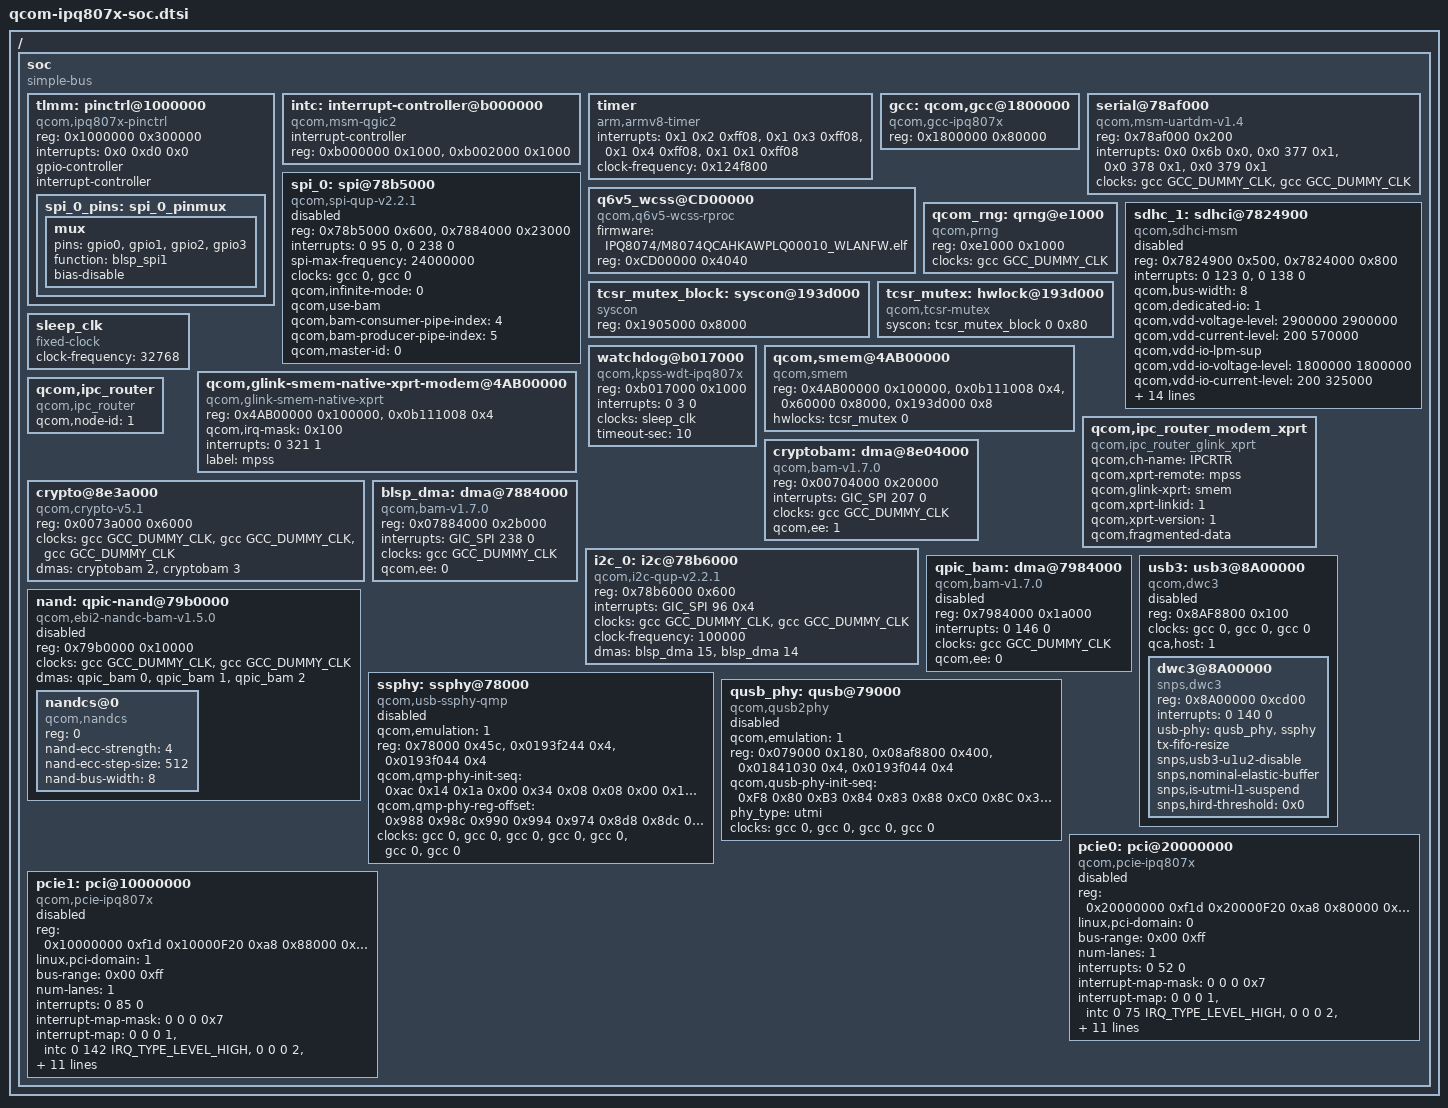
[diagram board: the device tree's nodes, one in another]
/*
 * Copyright (c) 2016, The Linux Foundation. All rights reserved.
 *
 * Permission to use, copy, modify, and/or distribute this software for any
 * purpose with or without fee is hereby granted, provided that the above
 * copyright notice and this permission notice appear in all copies.
 *
 * THE SOFTWARE IS PROVIDED "AS IS" AND THE AUTHOR DISCLAIMS ALL WARRANTIES
 * WITH REGARD TO THIS SOFTWARE INCLUDING ALL IMPLIED WARRANTIES OF
 * MERCHANTABILITY AND FITNESS. IN NO EVENT SHALL THE AUTHOR BE LIABLE FOR
 * ANY SPECIAL, DIRECT, INDIRECT, OR CONSEQUENTIAL DAMAGES OR ANY DAMAGES
 * WHATSOEVER RESULTING FROM LOSS OF USE, DATA OR PROFITS, WHETHER IN AN
 * ACTION OF CONTRACT, NEGLIGENCE OR OTHER TORTIOUS ACTION, ARISING OUT OF
 * OR IN CONNECTION WITH THE USE OR PERFORMANCE OF THIS SOFTWARE.
 */
#include <dt-bindings/reset/qcom,gcc-ipq807x.h>
#include <dt-bindings/interrupt-controller/arm-gic.h>

/ {
	soc: soc {
		#address-cells = <0x1>;
		#size-cells = <0x1>;
		ranges = <0x0 0x0 0x0 0xffffffff>;
		compatible = "simple-bus";

		tlmm: pinctrl@1000000 {
			compatible = "qcom,ipq807x-pinctrl";
			reg = <0x1000000 0x300000>;
			interrupts = <0x0 0xd0 0x0>;
			gpio-controller;
			#gpio-cells = <0x2>;
			interrupt-controller;
			#interrupt-cells = <0x2>;

			spi_0_pins: spi_0_pinmux {
				mux {
					pins = "gpio0", "gpio1", "gpio2", "gpio3";
					function = "blsp_spi1";
					bias-disable;
				};
			};
		};

		intc: interrupt-controller@b000000 {
			compatible = "qcom,msm-qgic2";
			interrupt-controller;
			#interrupt-cells = <0x3>;
			reg = <0xb000000 0x1000>,
			<0xb002000 0x1000>;
		};

		timer {
			compatible = "arm,armv8-timer";
			interrupts = <0x1 0x2 0xff08>,
				     <0x1 0x3 0xff08>,
				     <0x1 0x4 0xff08>,
				     <0x1 0x1 0xff08>;
			clock-frequency = <0x124f800>;
		};


		gcc: qcom,gcc@1800000 {
			compatible = "qcom,gcc-ipq807x";
			reg = <0x1800000 0x80000>;
			#clock-cells = <0x1>;
		};

		serial@78af000 {
			compatible = "qcom,msm-uartdm-v1.4", "qcom,msm-uartdm";
			reg = <0x78af000 0x200>;
			interrupts = <0x0 0x6b 0x0>,
					<0x0 377 0x1>,
					<0x0 378 0x1>,
					<0x0 379 0x1>;
			status = "ok";
			clocks = <&gcc GCC_DUMMY_CLK>,
				 <&gcc GCC_DUMMY_CLK>;
			clock-names = "core", "iface";
		};

		spi_0: spi@78b5000 { /* BLSP1 QUP1 */
			compatible = "qcom,spi-qup-v2.2.1";
			#address-cells = <1>;
			#size-cells = <0>;
			reg-names = "spi_physical", "spi_bam_physical";
			reg = <0x78b5000 0x600>,
				<0x7884000 0x23000>;
			interrupt-names = "spi_irq", "spi_bam_irq";
			interrupts = <0 95 0>, <0 238 0>;
			spi-max-frequency = <24000000>;
			clocks = <&gcc 0>, /*GCC_BLSP1_QUP1_SPI_APPS_CLK>,*/
				<&gcc 0>;/*GCC_BLSP1_AHB_CLK>;*/
			clock-names = "core", "iface";
			qcom,infinite-mode = <0>;
			qcom,use-bam;
			qcom,bam-consumer-pipe-index = <4>;
			qcom,bam-producer-pipe-index = <5>;
			qcom,master-id = <0>;
			status = "disabled";
		};

		q6v5_wcss@CD00000 {
			compatible = "qcom,q6v5-wcss-rproc";
			firmware = "IPQ8074/M8074QCAHKAWPLQ00010_WLANFW.elf";
			reg = <0xCD00000 0x4040>;
		};

		qcom_rng: qrng@e1000 {
			compatible = "qcom,prng";
			reg = <0xe1000 0x1000>;
			clocks = <&gcc GCC_DUMMY_CLK>;
			clock-names = "core";
		};

		sdhc_1: sdhci@7824900 {
			compatible = "qcom,sdhci-msm";
			reg = <0x7824900 0x500>, <0x7824000 0x800>;
			reg-names = "hc_mem", "core_mem";

			interrupts = <0 123 0>, <0 138 0>;
			interrupt-names = "hc_irq", "pwr_irq";

			qcom,bus-width = <8>;

			qcom,dedicated-io = <1>;

			/* device core power supply */
			qcom,vdd-voltage-level = <2900000 2900000>;
			qcom,vdd-current-level = <200 570000>;

			/* device communication power supply */
			qcom,vdd-io-lpm-sup;
			qcom,vdd-io-voltage-level = <1800000 1800000>;
			qcom,vdd-io-current-level = <200 325000>;
			qcom,vdd-io-always-on;

			qcom,cpu-dma-latency-us = <701>;
			qcom,msm-bus,name = "sdhc1";
			qcom,msm-bus,num-cases = <9>;
			qcom,msm-bus,num-paths = <1>;
			qcom,msm-bus,vectors-KBps = <78 512 0 0>, /* No vote */
				<78 512 1046 3200>,    /* 400 KB/s*/
				<78 512 52286 160000>, /* 20 MB/s */
				<78 512 65360 200000>, /* 25 MB/s */
				<78 512 130718 400000>, /* 50 MB/s */
				<78 512 261438 800000>, /* 100 MB/s */
				<78 512 261438 800000>, /* 200 MB/s */
				<78 512 261438 800000>, /* 400 MB/s */
				<78 512 1338562 4096000>; /* Max. bandwidth */
			qcom,bus-bw-vectors-bps = <0 400000 20000000 25000000 \
						50000000 100000000 200000000 \
						400000000 4294967295>;

			clocks = <&gcc GCC_DUMMY_CLK>,
				 <&gcc GCC_DUMMY_CLK>;
			clock-names = "iface_clk", "core_clk";
			qcom,large-address-bus;

			status = "disabled";
		};

		tcsr_mutex_block: syscon@193d000 {
			compatible = "syscon";
			reg = <0x1905000 0x8000>;
		};

		tcsr_mutex: hwlock@193d000 {
			compatible = "qcom,tcsr-mutex";
			syscon = <&tcsr_mutex_block 0 0x80>;
			#hwlock-cells = <1>;
		};

		sleep_clk: sleep_clk {
			compatible = "fixed-clock";
			clock-frequency = <32768>;
			#clock-cells = <0>;
		};

		watchdog@b017000 {
			compatible = "qcom,kpss-wdt-ipq807x";
			reg = <0xb017000 0x1000>;
			interrupt-names = "bark_irq";
			interrupts = <0 3 0>;
			clocks = <&sleep_clk>;
			timeout-sec = <10>;
		};

		qcom,smem@4AB00000 {
			compatible = "qcom,smem";
			reg = <0x4AB00000 0x100000>,
				<0x0b111008 0x4>,
				<0x60000 0x8000>,
				<0x193d000 0x8>;
			reg-names = "smem", "irq-reg-base",
				"aux-mem1", "smem_targ_info_reg";
			hwlocks = <&tcsr_mutex 0>;
		};

		qcom,glink-smem-native-xprt-modem@4AB00000 {
			compatible = "qcom,glink-smem-native-xprt";
			reg = <0x4AB00000 0x100000>, <0x0b111008 0x4>;
			reg-names = "smem", "irq-reg-base";
			qcom,irq-mask = <0x100>;
			interrupts = <0 321 1>;
			label = "mpss";
		};

		qcom,ipc_router {
			compatible = "qcom,ipc_router";
			qcom,node-id = <1>;
		};

		qcom,ipc_router_modem_xprt {
			compatible = "qcom,ipc_router_glink_xprt";
			qcom,ch-name = "IPCRTR";
			qcom,xprt-remote = "mpss";
			qcom,glink-xprt = "smem";
			qcom,xprt-linkid = <1>;
			qcom,xprt-version = <1>;
			qcom,fragmented-data;
		};

		cryptobam: dma@8e04000 {
			compatible = "qcom,bam-v1.7.0";
			reg = <0x00704000 0x20000>;
			interrupts = <GIC_SPI 207 0>;
			clocks = <&gcc GCC_DUMMY_CLK>;
			clock-names = "bam_clk";
			#dma-cells = <1>;
			qcom,ee = <1>;
		};

		crypto@8e3a000 {
			compatible = "qcom,crypto-v5.1";
			reg = <0x0073a000 0x6000>;
			clocks = <&gcc GCC_DUMMY_CLK>,
				<&gcc GCC_DUMMY_CLK>,
				<&gcc GCC_DUMMY_CLK>;
			clock-names = "iface", "bus", "core";
			dmas = <&cryptobam 2>, <&cryptobam 3>;
			dma-names = "rx", "tx";
		};

		blsp_dma: dma@7884000 {
			compatible = "qcom,bam-v1.7.0";
			reg = <0x07884000 0x2b000>;
			interrupts = <GIC_SPI 238 0>;
			clocks = <&gcc GCC_DUMMY_CLK>;
			clock-names = "bam_clk";
			#dma-cells = <1>;
			qcom,ee = <0>;
		};

		i2c_0: i2c@78b6000 {
			compatible = "qcom,i2c-qup-v2.2.1";
			#address-cells = <1>;
			#size-cells = <0>;
			reg = <0x78b6000 0x600>;
			interrupts = <GIC_SPI 96 0x4>;
			clocks = <&gcc GCC_DUMMY_CLK>,
				<&gcc GCC_DUMMY_CLK>;
			clock-names = "iface", "core";
			clock-frequency  = <100000>;
			dmas = <&blsp_dma 15>, <&blsp_dma 14>;
			dma-names = "rx", "tx";
		};

		qpic_bam: dma@7984000{
			compatible = "qcom,bam-v1.7.0";
			reg = <0x7984000 0x1a000>;
			interrupts = <0 146 0>;
			clocks = <&gcc GCC_DUMMY_CLK>;
			clock-names = "bam_clk";
			#dma-cells = <1>;
			qcom,ee = <0>;
			status = "disabled";
		};

		nand: qpic-nand@79b0000 {
			compatible = "qcom,ebi2-nandc-bam-v1.5.0";
			reg = <0x79b0000 0x10000>;
			#address-cells = <1>;
			#size-cells = <0>;
			clocks = <&gcc GCC_DUMMY_CLK>,
				<&gcc GCC_DUMMY_CLK>;
			clock-names = "core", "aon";

			dmas = <&qpic_bam 0>,
				<&qpic_bam 1>,
				<&qpic_bam 2>;
			dma-names = "tx", "rx", "cmd";
			status = "disabled";

			nandcs@0 {
				compatible = "qcom,nandcs";
				reg = <0>;
				#address-cells = <1>;
				#size-cells = <1>;

				nand-ecc-strength = <4>;
				nand-ecc-step-size = <512>;
				nand-bus-width = <8>;
			};
		};

		ssphy: ssphy@78000 {
			compatible = "qcom,usb-ssphy-qmp";
			qcom,emulation = <1>;
			reg = <0x78000 0x45c>,
				<0x0193f244 0x4>,
				<0x0193f044 0x4>;
			reg-names = "qmp_phy_base",
				    "vls_clamp_reg",
				    "tcsr_phy_clk_scheme_sel";
			qcom,qmp-phy-init-seq = <0xac 0x14 0x1a 0x00
						0x34 0x08 0x08 0x00
						0x174 0x30 0x30 0x00
						0x3c 0x06 0x06 0x00
						0xb4 0x00 0x00 0x00
						0xb8 0x08 0x08 0x00
						0x194 0x06 0x06 0x3e8
						0x19c 0x01 0x01 0x00
						0x178 0x00 0x00 0x00
						0xd0 0x82 0x82 0x00
						0xdc 0x55 0x55 0x00
						0xe0 0x55 0x55 0x00
						0xe4 0x03 0x03 0x00
						0x78 0x0b 0x0b 0x00
						0x84 0x16 0x16 0x00
						0x90 0x28 0x28 0x00
						0x108 0x80 0x80 0x00
						0x10c 0x00 0x00 0x00
						0x184 0x0a 0x0a 0x00
						0x4c 0x15 0x15 0x00
						0x50 0x34 0x34 0x00
						0x54 0x00 0x00 0x00
						0xc8 0x00 0x00 0x00
						0x18c 0x00 0x00 0x00
						0xcc 0x00 0x00 0x00
						0x128 0x00 0x00 0x00
						0x0c 0x0a 0x0a 0x00
						0x10 0x01 0x01 0x00
						0x1c 0x31 0x31 0x00
						0x20 0x01 0x01 0x00
						0x14 0x00 0x00 0x00
						0x18 0x00 0x00 0x00
						0x24 0xde 0xde 0x00
						0x28 0x07 0x07 0x00
						0x48 0x0f 0x0f 0x00
						0x70 0x0f 0x0f 0x00
						0x100 0x80 0x80 0x00
						0x440 0x0b 0x0b 0x00
						0x4d8 0x02 0x02 0x00
						0x4dc 0x6c 0x6c 0x00
						0x4e0 0xbb 0xbb 0x00
						0x508 0x77 0x77 0x00
						0x50c 0x80 0x80 0x00
						0x514 0x03 0x03 0x00
						0x51c 0x16 0x16 0x00
						0x448 0x75 0x75 0x00
						0x454 0x00 0x00 0x00
						0x40c 0x0a 0x0a 0x00
						0x41c 0x06 0x06 0x00
						0x510 0x00 0x00 0x00
						0x268 0x45 0x45 0x00
						0x2ac 0x12 0x12 0x00
						0x294 0x06 0x06 0x00
						0x254 0x00 0x00 0x00
						0x8c8 0x83 0x83 0x00
						0x8c4 0x02 0x02 0x00
						0x8cc 0x09 0x09 0x00
						0x8d0 0xa2 0xa2 0x00
						0x8d4 0x85 0x85 0x00
						0x880 0xd1 0xd1 0x00
						0x884 0x1f 0x1f 0x00
						0x888 0x47 0x47 0x00
						0x80c 0x9f 0x9f 0x00
						0x824 0x17 0x17 0x00
						0x828 0x0f 0x0f 0x00
						0x8b8 0x75 0x75 0x00
						0x8bc 0x13 0x13 0x00
						0x8b0 0x86 0x86 0x00
						0x8a0 0x04 0x04 0x00
						0x88c 0x44 0x44 0x00
						0x870 0xe7 0xe7 0x00
						0x874 0x03 0x03 0x00
						0x878 0x40 0x40 0x00
						0x87c 0x00 0x00 0x00
						0x9d8 0x88 0x88 0x00
						0xffffffff 0xffffffff 0x00 0x00>;
			qcom,qmp-phy-reg-offset = <0x988 0x98c 0x990 0x994
						0x974 0x8d8 0x8dc 0x804 0x800
						0x808>;

			clocks = <&gcc 0>,/*clk_gcc_usb3_aux_clk>,*/
				 <&gcc 0>,/*clk_gcc_usb3_pipe_clk>,*/
				 <&gcc 0>,/*clk_gcc_usb_phy_cfg_ahb_clk>,*/
				 <&gcc 0>,/*clk_gcc_usb3_phy_reset>,*/
				 <&gcc 0>,/*clk_gcc_usb3phy_phy_reset>,*/
				 <&gcc 0>,/*clk_bb_clk1>,*/
				 <&gcc 0>;/*clk_gcc_usb_ss_ref_clk>;*/

			clock-names = "aux_clk", "pipe_clk", "cfg_ahb_clk", "phy_reset",
				      "phy_phy_reset", "ref_clk_src", "ref_clk";

			status = "disabled";
		};

		qusb_phy: qusb@79000 {
			  compatible = "qcom,qusb2phy";
			  qcom,emulation = <1>;
			  reg = <0x079000 0x180>,
				<0x08af8800 0x400>,
				<0x01841030 0x4>,
				<0x0193f044 0x4>;
			  reg-names = "qusb_phy_base",
				  "qscratch_base",
				  "ref_clk_addr",
				  "tcsr_phy_clk_scheme_sel";

			  qcom,qusb-phy-init-seq = <0xF8 0x80
				  0xB3 0x84
				  0x83 0x88
				  0xC0 0x8C
				  0x30 0x08
				  0x79 0x0C
				  0x21 0x10
				  0x14 0x9C
				  0x9F 0x1C
				  0x00 0x18>;
			  phy_type= "utmi";

			  clocks = <&gcc 0>, /*clk_bb_clk1*/
				 <&gcc 0>, /*clk_gcc_qusb_ref_clk*/
				 <&gcc 0>, /*clk_gcc_usb_phy_cfg_ahb_clk*/
				 <&gcc 0>; /*clk_gcc_qusb2_phy_reset*/

			  clock-names = "ref_clk_src", "ref_clk", "cfg_ahb_clk",
				  "phy_reset";

			status = "disabled";
		};


		usb3: usb3@8A00000 {
			compatible = "qcom,dwc3";
			#address-cells = <1>;
			#size-cells = <1>;
			ranges;
			reg = <0x8AF8800 0x100>;
			reg-names = "qscratch_base";
			clocks = <&gcc 0>,/*GCC_USB3_MASTER_CLK*/
				<&gcc 0>,/*GCC_USB3_SLEEP_CLK*/
				<&gcc 0>;/*GCC_USB3_MOCK_UTMI_CLK>*/
			clock-names = "master",
				"sleep",
				"mock_utmi";
			qca,host = <1>;
			status = "disabled";

			dwc3@8A00000 {
				compatible = "snps,dwc3";
				reg = <0x8A00000 0xcd00>;
				interrupts = <0 140 0>;
				usb-phy = <&qusb_phy>, <&ssphy>;
				tx-fifo-resize;
				snps,usb3-u1u2-disable;
				snps,nominal-elastic-buffer;
				snps,is-utmi-l1-suspend;
				snps,hird-threshold = /bits/ 8 <0x0>;
			};
		};

		pcie0: pci@20000000 {
			compatible = "qcom,pcie-ipq807x";
			reg =  <0x20000000 0xf1d
				0x20000F20 0xa8
				0x80000 0x2000
				0x20100000 0x1000>;
			reg-names = "dbi", "elbi", "parf", "config";
			device_type = "pci";
			linux,pci-domain = <0>;
			bus-range = <0x00 0xff>;
			num-lanes = <1>;
			#address-cells = <3>;
			#size-cells = <2>;

			ranges = <0x81000000 0 0x20200000 0x20200000
				  0 0x00100000   /* downstream I/O */
				  0x82000000 0 0x20300000 0x20300000
				  0 0x00d00000>; /* non-prefetchable memory */

			interrupts = <0 52 0>;
			interrupt-names = "msi";
			#interrupt-cells = <1>;
			interrupt-map-mask = <0 0 0 0x7>;
			interrupt-map = <0 0 0 1 &intc 0 75
					 IRQ_TYPE_LEVEL_HIGH>, /* int_a */
					<0 0 0 2 &intc 0 78
					 IRQ_TYPE_LEVEL_HIGH>, /* int_b */
					<0 0 0 3 &intc 0 79
					 IRQ_TYPE_LEVEL_HIGH>, /* int_c */
					<0 0 0 4 &intc 0 83
					 IRQ_TYPE_LEVEL_HIGH>; /* int_d */
			clocks = <&gcc GCC_DUMMY_CLK>,
				 <&gcc GCC_DUMMY_CLK>,
				 <&gcc GCC_DUMMY_CLK>,
				 <&gcc GCC_DUMMY_CLK>,
				 <&gcc GCC_DUMMY_CLK>,
				 <&gcc GCC_DUMMY_CLK>,
				 <&gcc GCC_DUMMY_CLK>;
			clock-names = "boot",
				      "axi_m",
				      "axi_s",
				      "ahb",
				      "aux",
				      "pipe",
				      "phy";

			resets = <&gcc GCC_PCIE0_BCR>,
				 <&gcc GCC_PCIE0_PHY_BCR>,
				 <&gcc GCC_PCIE0PHY_PHY_BCR>;
			reset-names = "pci",
				      "phy",
				      "phy1";

			perst-gpio = <&tlmm 58 1>;
			status = "disabled";
		};

		pcie1: pci@10000000 {
			compatible = "qcom,pcie-ipq807x";
			reg =  <0x10000000 0xf1d
				0x10000F20 0xa8
				0x88000 0x2000
				0x10100000 0x1000>;
			reg-names = "dbi", "elbi", "parf", "config";
			device_type = "pci";
			linux,pci-domain = <1>;
			bus-range = <0x00 0xff>;
			num-lanes = <1>;
			#address-cells = <3>;
			#size-cells = <2>;

			ranges = <0x81000000 0 0x10200000 0x10200000
				  0 0x00100000   /* downstream I/O */
				  0x82000000 0 0x10300000 0x10300000
				  0 0x00d00000>; /* non-prefetchable memory */

			interrupts = <0 85 0>;
			interrupt-names = "msi";
			#interrupt-cells = <1>;
			interrupt-map-mask = <0 0 0 0x7>;
			interrupt-map = <0 0 0 1 &intc 0 142
					 IRQ_TYPE_LEVEL_HIGH>, /* int_a */
					<0 0 0 2 &intc 0 143
					 IRQ_TYPE_LEVEL_HIGH>, /* int_b */
					<0 0 0 3 &intc 0 144
					 IRQ_TYPE_LEVEL_HIGH>, /* int_c */
					<0 0 0 4 &intc 0 145
					 IRQ_TYPE_LEVEL_HIGH>; /* int_d */
			clocks = <&gcc GCC_DUMMY_CLK>,
				 <&gcc GCC_DUMMY_CLK>,
				 <&gcc GCC_DUMMY_CLK>,
				 <&gcc GCC_DUMMY_CLK>,
				 <&gcc GCC_DUMMY_CLK>,
				 <&gcc GCC_DUMMY_CLK>,
				 <&gcc GCC_DUMMY_CLK>;
			clock-names = "boot",
				      "axi_m",
				      "axi_s",
				      "ahb",
				      "aux",
				      "pipe",
				      "phy";

			resets = <&gcc GCC_PCIE0_BCR>,
				 <&gcc GCC_PCIE0_PHY_BCR>,
				 <&gcc GCC_PCIE0PHY_PHY_BCR>;
			reset-names = "pci",
				      "phy",
				      "phy1";

			perst-gpio = <&tlmm 61 1>;
			status = "disabled";
		};
	};
};
